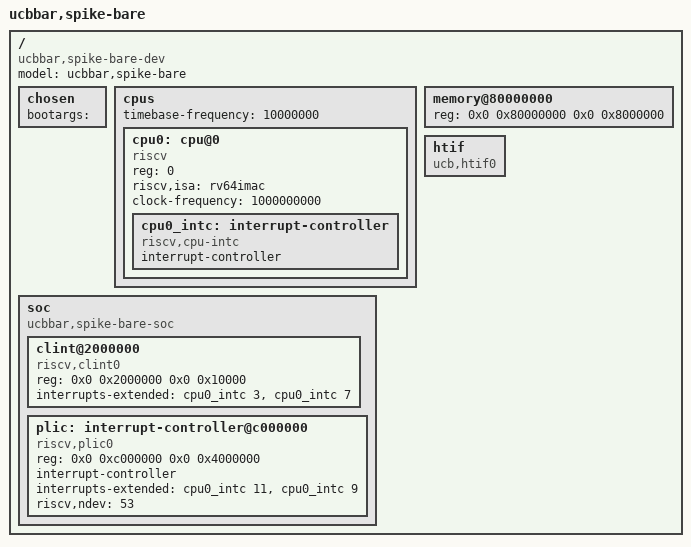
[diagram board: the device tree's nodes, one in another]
/dts-v1/;

/ {
    #address-cells = <2>;
    #size-cells = <2>;
    compatible = "ucbbar,spike-bare-dev";
    model = "ucbbar,spike-bare";

    chosen {
        bootargs = "";
    };

    cpus {
        #address-cells = <1>;
        #size-cells = <0>;
        timebase-frequency = <10000000>; // 10 MHz

        cpu0: cpu@0 {
            device_type = "cpu";
            reg = <0>;
            status = "okay";
            compatible = "riscv";
            riscv,isa = "rv64imac";
            clock-frequency = <1000000000>; // 1 GHz

            cpu0_intc: interrupt-controller {
                #interrupt-cells = <1>;
                interrupt-controller;
                compatible = "riscv,cpu-intc";
            };
        };
    };

    memory@80000000 {
        device_type = "memory";
        reg = <0x0 0x80000000 0x0 0x8000000>; // 128 MB
    };

    soc {
        #address-cells = <2>;
        #size-cells = <2>;
        compatible = "ucbbar,spike-bare-soc", "simple-bus";
        ranges;

        clint@2000000 {
            compatible = "riscv,clint0";
            reg = <0x0 0x2000000 0x0 0x10000>;
            interrupts-extended = <&cpu0_intc 3 &cpu0_intc 7>;
        };

        plic: interrupt-controller@c000000 {
            compatible = "riscv,plic0";
            reg = <0x0 0xc000000 0x0 0x4000000>;
            #interrupt-cells = <1>;
            interrupt-controller;
            interrupts-extended = <&cpu0_intc 11 &cpu0_intc 9>;
            riscv,ndev = <53>;
        };
    };

    htif {
        compatible = "ucb,htif0";
    };
};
